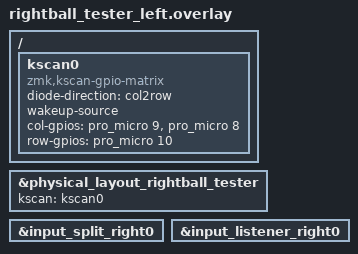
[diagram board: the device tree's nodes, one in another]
#include "rightball_tester.dtsi"

/ {
    kscan0: kscan0 {
        compatible = "zmk,kscan-gpio-matrix";
        diode-direction = "col2row";
        wakeup-source;

        col-gpios
            = <&pro_micro 9 GPIO_ACTIVE_HIGH>
            , <&pro_micro 8 GPIO_ACTIVE_HIGH>
            ;

        row-gpios
            = <&pro_micro 10 (GPIO_ACTIVE_HIGH | GPIO_PULL_DOWN)>
            ;
    };
};

&physical_layout_rightball_tester {
    kscan = <&kscan0>;
};
// == Input devices ==
// Input devices on peripheral parts
// Enabling input listeners and input-split to receive input events from peripherals
&input_split_right0 { status = "okay"; };
&input_listener_right0 { status = "okay"; };

